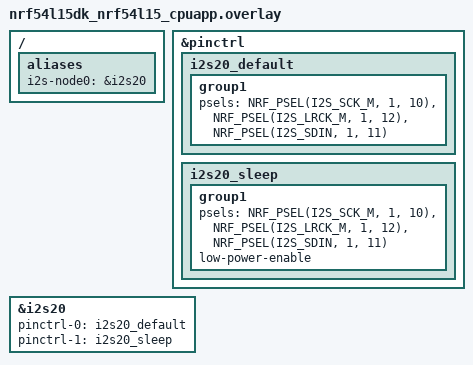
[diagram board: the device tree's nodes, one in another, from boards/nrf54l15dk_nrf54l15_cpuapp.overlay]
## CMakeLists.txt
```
# SPDX-License-Identifier: Apache-2.0

cmake_minimum_required(VERSION 3.20.0)
find_package(Zephyr REQUIRED HINTS $ENV{ZEPHYR_BASE})
project(bap_unicast_server_nrf54l15)

target_sources(app PRIVATE
  src/main.c
  src/stylus_hid.c
)

zephyr_library_include_directories(${ZEPHYR_BASE}/samples/bluetooth)
```

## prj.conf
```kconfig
CONFIG_AUDIO_DMIC=y
CONFIG_AUDIO=y
CONFIG_BT=y
CONFIG_LOG=y
CONFIG_BT_PERIPHERAL=y
CONFIG_BT_ISO_PERIPHERAL=y
CONFIG_BT_AUDIO=y
CONFIG_BT_BAP_UNICAST_SERVER=y
CONFIG_BT_ASCS=y
CONFIG_BT_ASCS_MAX_ASE_SNK_COUNT=1
CONFIG_BT_ASCS_MAX_ASE_SRC_COUNT=1

# Support an ISO channel per ASE
CONFIG_BT_ISO_MAX_CHAN=2

CONFIG_BT_AUDIO_CODEC_CFG_MAX_METADATA_SIZE=80

# Mandatory to support at least 1 for ASCS
CONFIG_BT_ATT_PREPARE_COUNT=8
CONFIG_BT_GATT_DYNAMIC_DB=y
CONFIG_BT_EXT_ADV=y
CONFIG_BT_DEVICE_NAME="nrf54l15_pdm_mic"
CONFIG_SW_CODEC_LC3_T2_SOFTWARE=y
CONFIG_FPU=y
CONFIG_NEWLIB_LIBC=y
CONFIG_BT_LOG_SNIFFER_INFO=y
CONFIG_THREAD_NAME=y
CONFIG_CLOCK_CONTROL=y
CONFIG_LC3_ENC_CHAN_MAX=1
CONFIG_BT_BONDABLE=y
CONFIG_BT_SMP=y
CONFIG_LOG_BUFFER_SIZE=4096

# Enable DK LED and Buttons library
CONFIG_DK_LIBRARY=y
CONFIG_BT_SECURITY_ERR_TO_STR=y
CONFIG_BT_SMP_ERR_TO_STR=y

CONFIG_BT_MAX_CONN=2
CONFIG_BT_ATT_TX_COUNT=5
CONFIG_BT_BAS=y
CONFIG_BT_HIDS=y
CONFIG_BT_HIDS_MAX_CLIENT_COUNT=2
CONFIG_BT_HIDS_DEFAULT_PERM_RW_ENCRYPT=y
CONFIG_BT_GATT_UUID16_POOL_SIZE=40
CONFIG_BT_GATT_CHRC_POOL_SIZE=20
CONFIG_BT_CONN_CTX=y
CONFIG_BT_DIS=y
CONFIG_BT_DIS_MANUF_NAME=y
CONFIG_BT_DIS_MANUF_NAME_STR="NordicSemiconductor"
CONFIG_BT_DIS_PNP=y
CONFIG_BT_DIS_PNP_VID_SRC=2
CONFIG_BT_DIS_PNP_VID=0x1915
CONFIG_BT_DIS_PNP_PID=0xEEEE
CONFIG_BT_DIS_PNP_VER=0x0100


CONFIG_MAIN_STACK_SIZE=2048
CONFIG_SYSTEM_WORKQUEUE_STACK_SIZE=2048

CONFIG_BT_SETTINGS=y
CONFIG_FLASH=y
CONFIG_FLASH_MAP=y
CONFIG_NVS=y
CONFIG_SETTINGS=y

CONFIG_GPIO=y

# The ACL connection interval needs to be scaled with 10ms
CONFIG_BT_PERIPHERAL_PREF_MIN_INT=8
CONFIG_BT_PERIPHERAL_PREF_MAX_INT=16


CONFIG_BT_PAC_SNK_LOC=y
CONFIG_BT_PAC_SNK=y

CONFIG_BT_PAC_SRC_LOC=y
CONFIG_BT_PAC_SRC=y


CONFIG_BT_ISO_TX_BUF_COUNT=3
CONFIG_BT_BUF_ACL_TX_COUNT=3
```

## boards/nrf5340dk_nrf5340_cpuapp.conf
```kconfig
# For LC3 the following configs are needed
CONFIG_FPU=y
CONFIG_LIBLC3=y
# The LC3 codec uses a large amount of stack. This app runs the codec in the work-queue, hence
# inctease stack size for that thread.
CONFIG_SYSTEM_WORKQUEUE_STACK_SIZE=8192

CONFIG_BT_BUF_EVT_RX_SIZE=255
CONFIG_BT_BUF_ACL_RX_SIZE=255
CONFIG_BT_BUF_ACL_TX_SIZE=251
CONFIG_BT_BUF_CMD_TX_SIZE=255

CONFIG_BT_TINYCRYPT_ECC=y
```

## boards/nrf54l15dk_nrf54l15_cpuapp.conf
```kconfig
# For LC3 the following configs are needed
CONFIG_FPU=y
#CONFIG_LIBLC3=y
# The LC3 codec uses a large amount of stack. This app runs the codec in the work-queue, hence
# inctease stack size for that thread.
CONFIG_SYSTEM_WORKQUEUE_STACK_SIZE=8192

CONFIG_BT_BUF_EVT_RX_SIZE=255
CONFIG_BT_BUF_ACL_RX_SIZE=255
CONFIG_BT_BUF_ACL_TX_SIZE=251
CONFIG_BT_BUF_CMD_TX_SIZE=255

CONFIG_BT_TINYCRYPT_ECC=y
```

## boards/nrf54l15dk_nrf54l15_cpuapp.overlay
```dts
/*
 * Copyright (c) 2024 Nordic Semiconductor ASA
 *
 * SPDX-License-Identifier: Apache-2.0
 */


/ {
	aliases {
		i2s-node0 = &i2s20;
    };
};

&pinctrl {
	i2s20_default: i2s20_default {
		group1 {
			psels =	<NRF_PSEL(I2S_SCK_M, 1, 10)>,
					<NRF_PSEL(I2S_LRCK_M, 1, 12)>,
					<NRF_PSEL(I2S_SDIN, 1, 11)>;
		};
	};

	i2s20_sleep: i2s20_sleep {
		group1 {
			psels = <NRF_PSEL(I2S_SCK_M, 1, 10)>,
					<NRF_PSEL(I2S_LRCK_M, 1, 12)>,
					<NRF_PSEL(I2S_SDIN, 1, 11)>;
			low-power-enable;
		};
	};
};

&i2s20 {
	status = "okay";
	pinctrl-0 = <&i2s20_default>;
	pinctrl-1 = <&i2s20_sleep>;
	pinctrl-names = "default", "sleep";
};
```

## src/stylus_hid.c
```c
/*
 * Copyright (c) 2021-2023 Nordic Semiconductor ASA
 *
 * SPDX-License-Identifier: Apache-2.0
 */

#include "stylus_hid.h"
#include <zephyr/sys/byteorder.h>
#include <bluetooth/services/hids.h>

static struct conn_mode {
	struct bt_conn *conn;
	bool in_boot_mode;
} conn_mode[CONFIG_BT_HIDS_MAX_CLIENT_COUNT];

void stylus_hid_remove_conn_object(struct bt_hids *hids_obj, struct bt_conn *conn)
{
    int err;

	err = bt_hids_disconnected(hids_obj, conn);
	if (err) {
		printk("Failed to notify HID service about disconnection\n");
	}    

	for (size_t i = 0; i < CONFIG_BT_HIDS_MAX_CLIENT_COUNT; i++) {
		if (conn_mode[i].conn == conn) {
			conn_mode[i].conn = NULL;
			conn_mode[i].in_boot_mode = false;
			return;
		}
	}
}

void stylus_hid_insert_conn_object(struct bt_hids *hids_obj, struct bt_conn *conn)
{
    int err;

	err = bt_hids_connected(hids_obj, conn);
	if (err) {
		printk("Failed to notify HID service about connection\n");
		return;
	}

	for (size_t i = 0; i < CONFIG_BT_HIDS_MAX_CLIENT_COUNT; i++) {
		if (!conn_mode[i].conn) {
			conn_mode[i].conn = conn;
			conn_mode[i].in_boot_mode = false;

			return;
		}
	}

	printk("Connection object could not be inserted %p\n", conn);
}

static void hids_pm_evt_handler(enum bt_hids_pm_evt evt, struct bt_conn *conn)
{
	char addr[BT_ADDR_LE_STR_LEN];
	size_t i;

	for (i = 0; i < CONFIG_BT_HIDS_MAX_CLIENT_COUNT; i++) {
		if (conn_mode[i].conn == conn) {
			break;
		}
	}

	if (i >= CONFIG_BT_HIDS_MAX_CLIENT_COUNT) {
		return;
	}

	bt_addr_le_to_str(bt_conn_get_dst(conn), addr, sizeof(addr));

	switch (evt) {
	case BT_HIDS_PM_EVT_BOOT_MODE_ENTERED:
		printk("Boot mode entered %s\n", addr);
		conn_mode[i].in_boot_mode = true;
		break;

	case BT_HIDS_PM_EVT_REPORT_MODE_ENTERED:
		printk("Report mode entered %s\n", addr);
		conn_mode[i].in_boot_mode = false;
		break;

	default:
		break;
	}
}

void stylus_hid_init(struct bt_hids *hids_obj)
{
	int err;
	struct bt_hids_init_param hids_init_param = {0};
	struct bt_hids_inp_rep *hids_inp_rep;
	static const uint8_t mouse_movement_mask[DIV_ROUND_UP(INPUT_REP_MOVEMENT_LEN, 8)] = {0};

	static const uint8_t report_map[] = {
		0x05, 0x01, /* Usage Page (Generic Desktop) */
		0x09, 0x02, /* Usage (Mouse) */

		0xA1, 0x01, /* Collection (Application) */

		/* Report ID 1: Mouse buttons + scroll/pan */
		0x85, 0x01,	  /* Report Id 1 */
		0x09, 0x01,	  /* Usage (Pointer) */
		0xA1, 0x00,	  /* Collection (Physical) */
		0x95, 0x05,	  /* Report Count (3) */
		0x75, 0x01,	  /* Report Size (1) */
		0x05, 0x09,	  /* Usage Page (Buttons) */
		0x19, 0x01,	  /* Usage Minimum (01) */
		0x29, 0x05,	  /* Usage Maximum (05) */
		0x15, 0x00,	  /* Logical Minimum (0) */
		0x25, 0x01,	  /* Logical Maximum (1) */
		0x81, 0x02,	  /* Input (Data, Variable, Absolute) */
		0x95, 0x01,	  /* Report Count (1) */
		0x75, 0x03,	  /* Report Size (3) */
		0x81, 0x01,	  /* Input (Constant) for padding */
		0x75, 0x08,	  /* Report Size (8) */
		0x95, 0x01,	  /* Report Count (1) */
		0x05, 0x01,	  /* Usage Page (Generic Desktop) */
		0x09, 0x38,	  /* Usage (Wheel) */
		0x15, 0x81,	  /* Logical Minimum (-127) */
		0x25, 0x7F,	  /* Logical Maximum (127) */
		0x81, 0x06,	  /* Input (Data, Variable, Relative) */
		0x05, 0x0C,	  /* Usage Page (Consumer) */
		0x0A, 0x38, 0x02, /* Usage (AC Pan) */
		0x95, 0x01,	  /* Report Count (1) */
		0x81, 0x06,	  /* Input (Data,Value,Relative,Bit Field) */
		0xC0,		  /* End Collection (Physical) */

		/* Report ID 2: Mouse motion */
		0x85, 0x02,	  /* Report Id 2 */
		0x09, 0x01,	  /* Usage (Pointer) */
		0xA1, 0x00,	  /* Collection (Physical) */
		0x75, 0x0C,	  /* Report Size (12) */
		0x95, 0x02,	  /* Report Count (2) */
		0x05, 0x01,	  /* Usage Page (Generic Desktop) */
		0x09, 0x30,	  /* Usage (X) */
		0x09, 0x31,	  /* Usage (Y) */
		0x16, 0x01, 0xF8, /* Logical maximum (2047) */
		0x26, 0xFF, 0x07, /* Logical minimum (-2047) */
		0x81, 0x06,	  /* Input (Data, Variable, Relative) */
		0xC0,		  /* End Collection (Physical) */
		0xC0,		  /* End Collection (Application) */

		/* Report ID 3: Advanced buttons */
		0x05, 0x0C, /* Usage Page (Consumer) */
		0x09, 0x01, /* Usage (Consumer Control) */
		0xA1, 0x01, /* Collection (Application) */
		0x85, 0x03, /* Report Id (3) */
		0x15, 0x00, /* Logical minimum (0) */
		0x25, 0x01, /* Logical maximum (1) */
		0x75, 0x01, /* Report Size (1) */
		0x95, 0x01, /* Report Count (1) */

		0x09, 0xCD,	  /* Usage (Play/Pause) */
		0x81, 0x06,	  /* Input (Data,Value,Relative,Bit Field) */
		0x0A, 0x83, 0x01, /* Usage (Consumer Control Configuration) */
		0x81, 0x06,	  /* Input (Data,Value,Relative,Bit Field) */
		0x09, 0xB5,	  /* Usage (Scan Next Track) */
		0x81, 0x06,	  /* Input (Data,Value,Relative,Bit Field) */
		0x09, 0xB6,	  /* Usage (Scan Previous Track) */
		0x81, 0x06,	  /* Input (Data,Value,Relative,Bit Field) */

		0x09, 0xEA,	  /* Usage (Volume Down) */
		0x81, 0x06,	  /* Input (Data,Value,Relative,Bit Field) */
		0x09, 0xE9,	  /* Usage (Volume Up) */
		0x81, 0x06,	  /* Input (Data,Value,Relative,Bit Field) */
		0x0A, 0x25, 0x02, /* Usage (AC Forward) */
		0x81, 0x06,	  /* Input (Data,Value,Relative,Bit Field) */
		0x0A, 0x24, 0x02, /* Usage (AC Back) */
		0x81, 0x06,	  /* Input (Data,Value,Relative,Bit Field) */
		0xC0		  /* End Collection */
	};

	hids_init_param.rep_map.data = report_map;
	hids_init_param.rep_map.size = sizeof(report_map);

	hids_init_param.info.bcd_hid = BASE_USB_HID_SPEC_VERSION;
	hids_init_param.info.b_country_code = 0x00;
	hids_init_param.info.flags = (BT_HIDS_REMOTE_WAKE | BT_HIDS_NORMALLY_CONNECTABLE);

	hids_inp_rep = &hids_init_param.inp_rep_group_init.reports[0];
	hids_inp_rep->size = INPUT_REP_BUTTONS_LEN;
	hids_inp_rep->id = INPUT_REP_REF_BUTTONS_ID;
	hids_init_param.inp_rep_group_init.cnt++;

	hids_inp_rep++;
	hids_inp_rep->size = INPUT_REP_MOVEMENT_LEN;
	hids_inp_rep->id = INPUT_REP_REF_MOVEMENT_ID;
	hids_inp_rep->rep_mask = mouse_movement_mask;
	hids_init_param.inp_rep_group_init.cnt++;

	hids_inp_rep++;
	hids_inp_rep->size = INPUT_REP_MEDIA_PLAYER_LEN;
	hids_inp_rep->id = INPUT_REP_REF_MPLAYER_ID;
	hids_init_param.inp_rep_group_init.cnt++;

	hids_init_param.is_mouse = true;
	hids_init_param.pm_evt_handler = hids_pm_evt_handler;

	err = bt_hids_init(hids_obj, &hids_init_param);
	__ASSERT(err == 0, "HIDS initialization failed\n");
}

void stylus_hid_mouse_movement_send(struct bt_hids *hids_obj, int16_t x_delta, int16_t y_delta)
{
	for (size_t i = 0; i < CONFIG_BT_HIDS_MAX_CLIENT_COUNT; i++) {

		if (!conn_mode[i].conn) {
			continue;
		}

		if (conn_mode[i].in_boot_mode) {
			x_delta = MAX(MIN(x_delta, SCHAR_MAX), SCHAR_MIN);
			y_delta = MAX(MIN(y_delta, SCHAR_MAX), SCHAR_MIN);

			bt_hids_boot_mouse_inp_rep_send(hids_obj, conn_mode[i].conn, NULL,
							(int8_t)x_delta, (int8_t)y_delta, NULL);
		} else {
			uint8_t x_buff[2];
			uint8_t y_buff[2];
			uint8_t buffer[INPUT_REP_MOVEMENT_LEN];

			int16_t x = MAX(MIN(x_delta, 0x07ff), -0x07ff);
			int16_t y = MAX(MIN(y_delta, 0x07ff), -0x07ff);

			/* Convert to little-endian. */
			sys_put_le16(x, x_buff);
			sys_put_le16(y, y_buff);

			/* Encode report. */
			BUILD_ASSERT(sizeof(buffer) == 3,
				     "Only 2 axis, 12-bit each, are supported");

			buffer[0] = x_buff[0];
			buffer[1] = (y_buff[0] << 4) | (x_buff[1] & 0x0f);
			buffer[2] = (y_buff[1] << 4) | (y_buff[0] >> 4);

			bt_hids_inp_rep_send(hids_obj, conn_mode[i].conn, INPUT_REP_MOVEMENT_INDEX,
					     buffer, sizeof(buffer), NULL);
		}
	}
}
```

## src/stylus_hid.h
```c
/*
 * Copyright (c) 2021-2023 Nordic Semiconductor ASA
 *
 * SPDX-License-Identifier: Apache-2.0
 */
#ifndef HID_H
#define HID_H

#include <zephyr/bluetooth/conn.h>
#include <bluetooth/services/hids.h>

#define BASE_USB_HID_SPEC_VERSION 0x0101

/* Number of pixels by which the cursor is moved when a button is pushed. */
#define MOVEMENT_SPEED		   10
/* Number of input reports in this application. */
#define INPUT_REPORT_COUNT	   3
/* Length of Mouse Input Report containing button data. */
#define INPUT_REP_BUTTONS_LEN	   3
/* Length of Mouse Input Report containing movement data. */
#define INPUT_REP_MOVEMENT_LEN	   3
/* Length of Mouse Input Report containing media player data. */
#define INPUT_REP_MEDIA_PLAYER_LEN 1
/* Index of Mouse Input Report containing button data. */
#define INPUT_REP_BUTTONS_INDEX	   0
/* Index of Mouse Input Report containing movement data. */
#define INPUT_REP_MOVEMENT_INDEX   1
/* Index of Mouse Input Report containing media player data. */
#define INPUT_REP_MPLAYER_INDEX	   2
/* Id of reference to Mouse Input Report containing button data. */
#define INPUT_REP_REF_BUTTONS_ID   1
/* Id of reference to Mouse Input Report containing movement data. */
#define INPUT_REP_REF_MOVEMENT_ID  2
/* Id of reference to Mouse Input Report containing media player data. */
#define INPUT_REP_REF_MPLAYER_ID   3

void stylus_hid_remove_conn_object(struct bt_hids *hids_obj, struct bt_conn *conn);
void stylus_hid_insert_conn_object(struct bt_hids *hids_obj,struct bt_conn *conn);
void stylus_hid_init(struct bt_hids *hids_obj);
void stylus_hid_mouse_movement_send(struct bt_hids *hids_obj, int16_t x_delta, int16_t y_delta);

#endif
```
